# STM32G563xx register map
File version: 1.0
Registers are 32-bit, read-write, reset 0x0 unless marked. A register's access mark holds for its fields unless they carry their own. Offsets are from the block's base; [hi:lo] are bit positions; {n}, {i} and the like mark numbered series.

## POSENC1 — Position encoder interface (POSENC)
Base 0x44013800
Same registers: POSENC2 0x44017800
? CTRLR — POSENC Hiperface-DSL register CTRLR
? VERSION_INFO3 (alternate view of CTRLR) — POSENC EnDat3 register VERSION_INFO
? INSTANTIATION_INFO3 — POSENC EnDat3 register INSTANTIATION_INFO
? MASTER_QMR (alternate view of INSTANTIATION_INFO3) — POSENC Hiperface-DSL register MASTER_QMR
? CONFIG_03 — POSENC EnDat3 register CONFIG_0
? EVENTR (alternate view of CONFIG_03) — POSENC Hiperface-DSL register EVENTR
? CONFIG_13 — POSENC EnDat3 register CONFIG_1
? MASKR (alternate view of CONFIG_13) — POSENC Hiperface-DSL register MASKR
? CONFIG_23 — POSENC EnDat3 register CONFIG_2
? EDGESR (alternate view of CONFIG_23) — POSENC Hiperface-DSL register EDGESR
? CONFIG_3 — POSENC EnDat3 register CONFIG_3
? DELAYR (alternate view of CONFIG_3) — POSENC Hiperface-DSL register DELAYR
? CONFIG_43 — POSENC EnDat3 register CONFIG_4
? VRS_RELR (alternate view of CONFIG_43) — POSENC Hiperface-DSL register VRS_RELR
? ENC_IDR — POSENC Hiperface-DSL register ENC_IDR
? BG_IRQ_MASK3 — POSENC EnDat3 register BG_IRQ_MASK
? FPOSSTR (alternate view of BG_IRQ_MASK3) — POSENC Hiperface-DSL register FPOSSTR
? FG_IRQ{i}_MASK3 (i=0..2) — POSENC EnDat3 register FG_IRQ{i}_MASK
? FPOSMT1 (alternate view of FG_IRQ0_MASK3) — POSENC Hiperface-DSL register FPOSMT1
? FPOSMT2 (alternate view of FG_IRQ1_MASK3) — POSENC Hiperface-DSL register FPOSMT2
? VELR (alternate view of FG_IRQ2_MASK3) — POSENC Hiperface-DSL register VELR
? SAFETY_PACKET_03 — POSENC EnDat3 register SAFETY_PACKET_0
? SAFETY_PACKET_13 — POSENC EnDat3 register SAFETY_PACKET_1
? VPOSST (alternate view of SAFETY_PACKET_13) — POSENC Hiperface-DSL register VPOSST
? VPOSMT1 — POSENC Hiperface-DSL register VPOSMT1
? VPOSMT2 — POSENC Hiperface-DSL register VPOSMT2
? VPOSCRC — POSENC Hiperface-DSL register VPOSCRC
? VPCBUFA — POSENC Hiperface-DSL register VPCBUFA
? VPCBUFB — POSENC Hiperface-DSL register VPCBUFB
? VPCBUFC — POSENC Hiperface-DSL register VPCBUFC
? LOFFR — POSENC Hiperface-DSL register LOFFR
? PC_ADDR — POSENC Hiperface-DSL register PC_ADDR
? PC_OFFR — POSENC Hiperface-DSL register PC_OFFR
? PC_ADDOFR — POSENC Hiperface-DSL register PC_ADDOFR
? PC_CTRLR — POSENC Hiperface-DSL register PC_CTRLR
? PIPE_SR — POSENC Hiperface-DSL register PIPE_SR
? PIPE_D — POSENC Hiperface-DSL register PIPE_D
? SAFE_CTRL — POSENC Hiperface-DSL register SAFE_CTRL
? SAFE_SUM — POSENC Hiperface-DSL register SAFE_SUM
? S_PC_DATA — POSENC Hiperface-DSL register S_PC_DATA
? ACC_EE_CNT — POSENC Hiperface-DSL register ACC_EE_CNT
? MAXACC — POSENC Hiperface-DSL register MAXACC
? MAXDEV — POSENC Hiperface-DSL register MAXDEV
? EVENT_S — POSENC Hiperface-DSL register EVENT_S
? MASK_S — POSENC Hiperface-DSL register MASK_S
? DUMMY — POSENC Hiperface-DSL register DUMMY
? ST{i} (i=0..7) — POSENC Hiperface-DSL register ST{i}
? SRSSI — POSENC Hiperface-DSL register SRSSI
? MAIL — POSENC Hiperface-DSL register MAIL
? PING — POSENC Hiperface-DSL register PING
? IRQ_CLEAR3 — POSENC EnDat3 register IRQ_CLEAR
? BG_REQ_03 — POSENC EnDat3 register BG_REQ_0
? BG_REQ_13 — POSENC EnDat3 register BG_REQ_1
? BG_REQ_23 — POSENC EnDat3 register BG_REQ_2
? BG_RSP_03 — POSENC EnDat3 register BG_RSP_0
? BG_RSP_13 — POSENC EnDat3 register BG_RSP_1
? FG_REQ_03 — POSENC EnDat3 register FG_REQ_0
? FG_REQ_13 — POSENC EnDat3 register FG_REQ_1
? SC_STATUS_03 — POSENC EnDat3 register SC_STATUS_0
? SC_STATUS_13 — POSENC EnDat3 register SC_STATUS_1
? COUNTERS3 — POSENC EnDat3 register COUNTERS
? FG_STATUS3 — POSENC EnDat3 register FG_STATUS
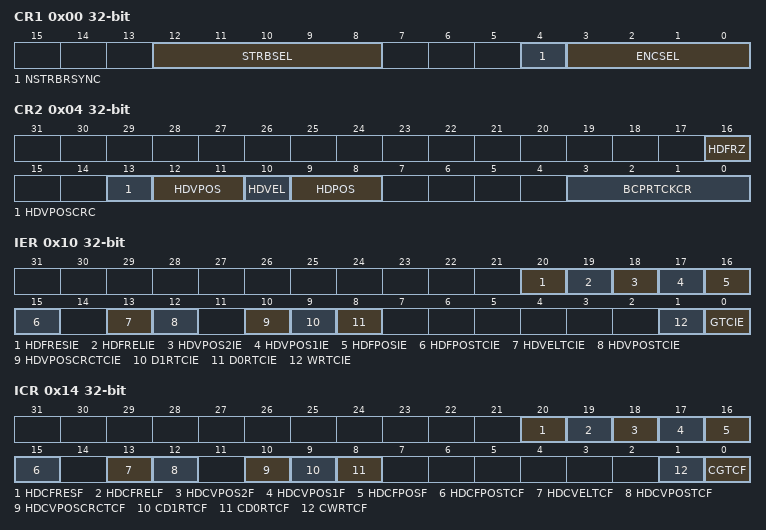
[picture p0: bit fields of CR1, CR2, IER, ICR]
0x00 CR1 — POSENC control register 1
  [12:8] STRBSEL — Strobe selection
  [4] NSTRBRSYNC — Strobe re-synchronization
  [3:0] ENCSEL — Encoder selection
0x04 CR2 — POSENC control register 2
  [16] HDFRZ — Hiperface-DSL freeze
  [13] HDVPOSCRC
  [12:11] HDVPOS
  [10] HDVEL
  [9:8] HDPOS
  [3:0] BCPRTCKCR — Biss-C specific
0x10 IER — POSENC interrupt enable register
  [20] HDFRESIE, [19] HDFRELIE, [18] HDVPOS2IE, [17] HDVPOS1IE, [16] HDFPOSIE, [15] HDFPOSTCIE, [13] HDVELTCIE, [12] HDVPOSTCIE, [10] HDVPOSCRCTCIE, [9] D1RTCIE, [8] D0RTCIE, [1] WRTCIE, [0] GTCIE
0x14 ICR — POSENC interrupt clear register
  [20] HDCFRESF, [19] HDCFRELF, [18] HDCVPOS2F, [17] HDCVPOS1F, [16] HDCFPOSF, [15] HDCFPOSTCF, [13] HDCVELTCF, [12] HDCVPOSTCF, [10] HDCVPOSCRCTCF, [9] CD1RTCF, [8] CD0RTCF, [1] CWRTCF, [0] CGTCF
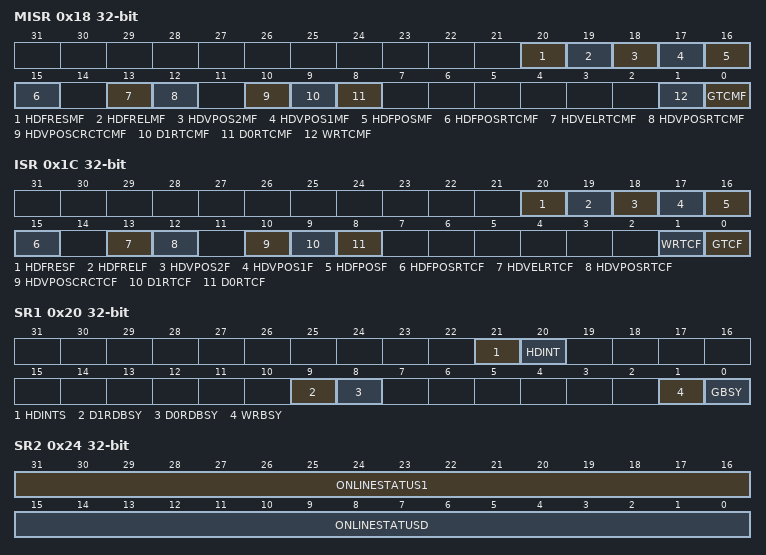
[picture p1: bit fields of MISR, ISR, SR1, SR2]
0x18 MISR — POSENC masked interrupt status register
  [20] HDFRESMF, [19] HDFRELMF, [18] HDVPOS2MF, [17] HDVPOS1MF, [16] HDFPOSMF, [15] HDFPOSRTCMF, [13] HDVELRTCMF, [12] HDVPOSRTCMF, [10] HDVPOSCRCTCMF, [9] D1RTCMF, [8] D0RTCMF, [1] WRTCMF, [0] GTCMF
0x1C ISR — POSENC interrupt status register
  [20] HDFRESF, [19] HDFRELF, [18] HDVPOS2F, [17] HDVPOS1F, [16] HDFPOSF, [15] HDFPOSRTCF, [13] HDVELRTCF, [12] HDVPOSRTCF, [10] HDVPOSCRCTCF, [9] D1RTCF, [8] D0RTCF, [1] WRTCF, [0] GTCF
0x20 SR1 ro — POSENC interrupt status register 1
  [21] HDINTS
  [20] HDINT
  [9] D1RDBSY — Data 1 read busy
  [8] D0RDBSY — Data 0 read busy
  [1] WRBSY — Write busy
  [0] GBSY — Global busy
0x24 SR2 ro — POSENC interrupt status register 2
  [31:16] ONLINESTATUS1, [15:0] ONLINESTATUSD
0x28 SR3 ro — POSENC interrupt status register 3
  [15:0] ONLINESTATUS2
0x204 D0AR — POSENC data 0 address register
  [7:0] D0ADD — Data 0 address
0x208 D1AR — POSENC data 1 address register
  [7:0] D1ADD — Data 1 address
0x304 D0R ro — POSENC data 0 register
  [31:0] D0 — Data 0 value
0x308 D1R ro — POSENC data 1 register
  [31:0] D1 — Data 1 value
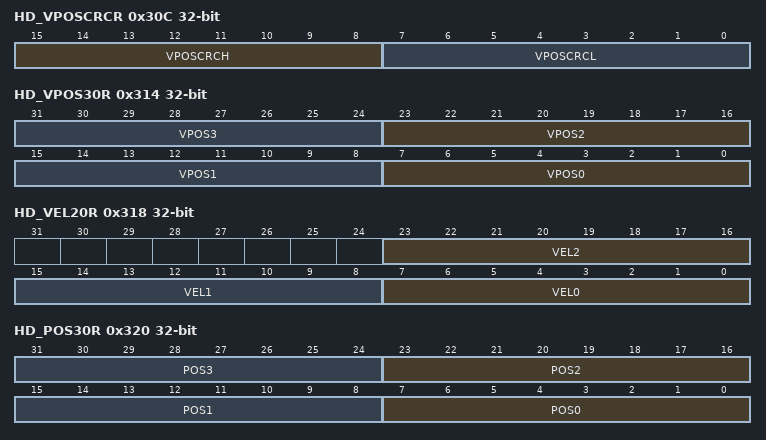
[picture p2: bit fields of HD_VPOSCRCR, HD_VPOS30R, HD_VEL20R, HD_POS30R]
0x30C HD_VPOSCRCR ro — POSENC Hiperface-DSL safe position 1 CRC register
  [15:8] VPOSCRCH, [7:0] VPOSCRCL
0x310 HD_VPOS4R ro — POSENC Hiperface-DSL safe position 1 VPOS4 register
  [7:0] VPOS4
0x314 HD_VPOS30R ro — POSENC Hiperface-DSL safe position 1 VPOS3_0 register
  [8n+7:8n] VPOS{n} (n=0..3)
0x318 HD_VEL20R ro — POSENC Hiperface-DSL safe position 1 VEL2_0 register
  [23:16] VEL2, [15:8] VEL1, [7:0] VEL0
0x31C HD_POS4R ro — POSENC Hiperface-DSL fast position POS4 register
  [7:0] POS4
0x320 HD_POS30R ro — POSENC Hiperface-DSL fast position POS3_0 register
  [8n+7:8n] POS{n} (n=0..3)
